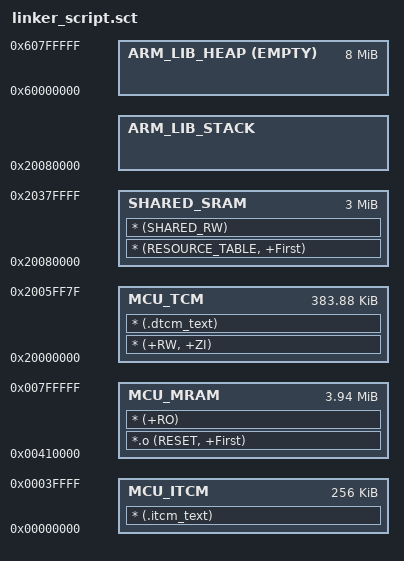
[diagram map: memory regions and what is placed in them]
;******************************************************************************
;
; Scatter file for Keil linker configuration.
;
;******************************************************************************
LR_1 0x00410000
{
    MCU_MRAM 0x00410000 0x003F0000
    {
        *.o (RESET, +First)
        * (+RO)
    }

    MCU_ITCM 0x00000000 0x00040000
    {
        * (.itcm_text)
    }

    ;MCU_TCM dollar{rw_base} dollar{rw_size}
    ;The next line is a temporary workaround while FPGA doesn't have SSRAM. The above line is actually correct (replace dollar with the dollar sign)
    MCU_TCM 0x20000000 (0x00060000-0x80)
    {
        * (+RW, +ZI)
        * (.dtcm_text)
    }

    ARM_LIB_HEAP  0x60000000 EMPTY  0x00800000
    {   ; Reserve empty region for heap
    }

    ;SHARED_SRAM dollar{shared_base} dollar{shared_size}
    ;The next line is a temporary workaround while FPGA doesn't have SSRAM. The above line is actually correct (replace dollar with the dollar sign)
    SHARED_SRAM 0x20080000 0x00300000
    {
        * (RESOURCE_TABLE, +First)
        * (SHARED_RW)
    }

    ARM_LIB_STACK 0x20080000 EMPTY - 0x00020000
    {   ; Reserve empty region for stack
    }


}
